# MDR1986VK01 register map
File version: 1.0.2
Registers are 32-bit, read-write, no defined reset value unless marked. A register's access mark holds for its fields unless they carry their own. Offsets are from the block's base; [hi:lo] are bit positions; {n}, {i} and the like mark numbered series; 'fields as' and 'values as' point back to an identical list.

## MDR_PWM0 — MDR_PWM0 description
Base 0x4009E000
Same registers: MDR_PWM{n} {0x4009E000+0x1000*n} (n=1..8)
0x00 TBPRD — TBPRD description
0x08 TBPHS — TBPHS description
0x0C TBCTR — TBCTR description
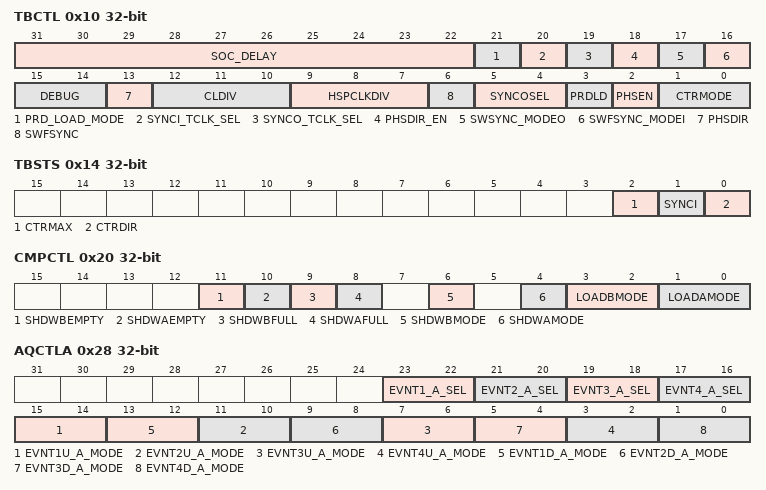
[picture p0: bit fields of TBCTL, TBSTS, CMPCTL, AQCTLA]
0x10 TBCTL — TBCTL description
  [31:22] SOC_DELAY — SOC_DELAY description
  [21] PRD_LOAD_MODE — PRD_LOAD_MODE description
  [20] SYNCI_TCLK_SEL — SYNCI_TCLK_SEL description
  [19] SYNCO_TCLK_SEL — SYNCO_TCLK_SEL description
  [18] PHSDIR_EN — PHSDIR_EN description
  [17] SWSYNC_MODEO — SWSYNC_MODEO description
  [16] SWFSYNC_MODEI — SWFSYNC_MODEI description
  [15:14] DEBUG — DEBUG description
  [13] PHSDIR — PHSDIR description
  [12:10] CLDIV — CLDIV description
  [9:7] HSPCLKDIV — HSPCLKDIV description
  [6] SWFSYNC — SWFSYNC description
  [5:4] SYNCOSEL — SYNCOSEL description
  [3] PRDLD — PRDLD description
  [2] PHSEN — PHSEN description
  [1:0] CTRMODE — CTRMODE description
0x14 TBSTS — TBSTS description
  [2] CTRMAX — CTRMAX description
  [1] SYNCI — SYNCI description
  [0] CTRDIR — CTRDIR description
0x18 CMPA — CMPA description
0x1C CMPB — CMPB description
0x20 CMPCTL — CMPCTL description
  [11] SHDWBEMPTY — SHDWBEMPTY description
  [10] SHDWAEMPTY — SHDWAEMPTY description
  [9] SHDWBFULL — SHDWBFULL description
  [8] SHDWAFULL — SHDWAFULL description
  [6] SHDWBMODE — SHDWBMODE description
  [4] SHDWAMODE — SHDWAMODE description
  [3:2] LOADBMODE — LOADBMODE description
  [1:0] LOADAMODE — LOADAMODE description
0x28 AQCTLA — AQCTLA description
  [25-2n:24-2n] EVNT{n}_A_SEL (n=1..4) — EVNT{n}_A_SEL description
  [19-4n:18-4n] EVNT{n}U_A_MODE (n=1..4) — EVNT{n}U_A_MODE description
  [17-4n:16-4n] EVNT{n}D_A_MODE (n=1..4) — EVNT{n}D_A_MODE description
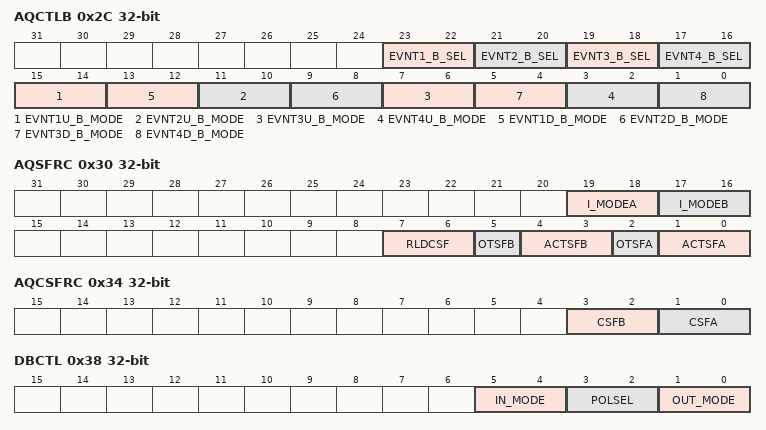
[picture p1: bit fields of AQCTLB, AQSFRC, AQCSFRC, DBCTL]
0x2C AQCTLB — AQCTLB description
  [25-2n:24-2n] EVNT{n}_B_SEL (n=1..4) — EVNT{n}_B_SEL description
  [19-4n:18-4n] EVNT{n}U_B_MODE (n=1..4) — EVNT{n}U_B_MODE description
  [17-4n:16-4n] EVNT{n}D_B_MODE (n=1..4) — EVNT{n}D_B_MODE description
0x30 AQSFRC — AQSFRC description
  [19:18] I_MODEA — I_MODEA description
  [17:16] I_MODEB — I_MODEB description
  [7:6] RLDCSF — RLDCSF description
  [5] OTSFB — OTSFB description
  [4:3] ACTSFB — ACTSFB description
  [2] OTSFA — OTSFA description
  [1:0] ACTSFA — ACTSFA description
0x34 AQCSFRC — AQCSFRC description
  [3:2] CSFB — CSFB description
  [1:0] CSFA — CSFA description
0x38 DBCTL — DBCTL description
  [5:4] IN_MODE — IN_MODE description
  [3:2] POLSEL — POLSEL description
  [1:0] OUT_MODE — OUT_MODE description
0x3C DBRED — DBRED description
0x40 DBFED — DBFED description
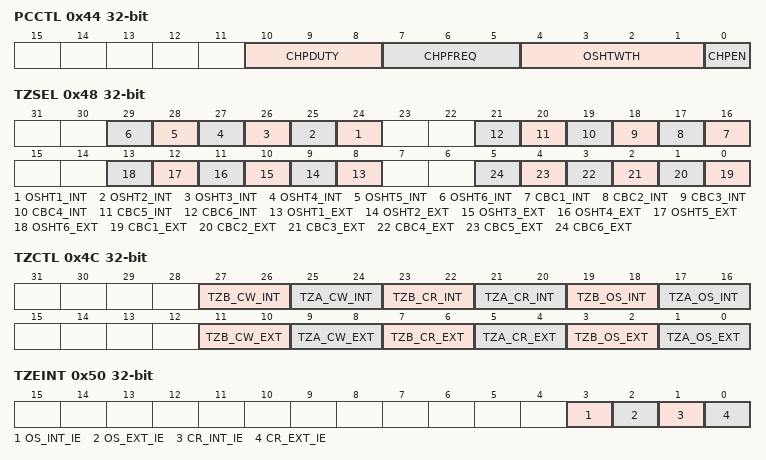
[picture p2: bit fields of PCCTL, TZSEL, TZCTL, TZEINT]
0x44 PCCTL — PCCTL description
  [10:8] CHPDUTY — CHPDUTY description
  [7:5] CHPFREQ — CHPFREQ description
  [4:1] OSHTWTH — OSHTWTH description
  [0] CHPEN — CHPEN description
0x48 TZSEL — TZSEL description
  [n+23] OSHT{n}_INT (n=1..6) — OSHT{n}_INT description
  [n+15] CBC{n}_INT (n=1..6) — CBC{n}_INT description
  [n+7] OSHT{n}_EXT (n=1..6) — OSHT{n}_EXT description
  [n-1] CBC{n}_EXT (n=1..6) — CBC{n}_EXT description
0x4C TZCTL — TZCTL description
  [27:26] TZB_CW_INT — TZB_CW_INT description
  [25:24] TZA_CW_INT — TZA_CW_INT description
  [23:22] TZB_CR_INT — TZB_CR_INT description
  [21:20] TZA_CR_INT — TZA_CR_INT description
  [19:18] TZB_OS_INT — TZB_OS_INT description
  [17:16] TZA_OS_INT — TZA_OS_INT description
  [11:10] TZB_CW_EXT — TZB_CW_EXT description
  [9:8] TZA_CW_EXT — TZA_CW_EXT description
  [7:6] TZB_CR_EXT — TZB_CR_EXT description
  [5:4] TZA_CR_EXT — TZA_CR_EXT description
  [3:2] TZB_OS_EXT — TZB_OS_EXT description
  [1:0] TZA_OS_EXT — TZA_OS_EXT description
0x50 TZEINT — TZEINT description
  [3] OS_INT_IE — OS_INT_IE description
  [2] OS_EXT_IE — OS_EXT_IE description
  [1] CR_INT_IE — CR_INT_IE description
  [0] CR_EXT_IE — CR_EXT_IE description
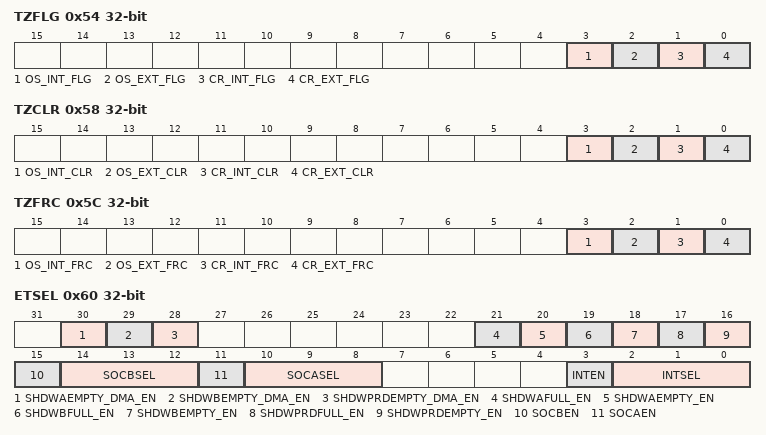
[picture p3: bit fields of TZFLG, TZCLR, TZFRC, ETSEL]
0x54 TZFLG — TZFLG description
  [3] OS_INT_FLG — OS_INT_FLG description
  [2] OS_EXT_FLG — OS_EXT_FLG description
  [1] CR_INT_FLG — CR_INT_FLG description
  [0] CR_EXT_FLG — CR_EXT_FLG description
0x58 TZCLR — TZCLR description
  [3] OS_INT_CLR — OS_INT_CLR description
  [2] OS_EXT_CLR — OS_EXT_CLR description
  [1] CR_INT_CLR — CR_INT_CLR description
  [0] CR_EXT_CLR — CR_EXT_CLR description
0x5C TZFRC — TZFRC description
  [3] OS_INT_FRC — OS_INT_FRC description
  [2] OS_EXT_FRC — OS_EXT_FRC description
  [1] CR_INT_FRC — CR_INT_FRC description
  [0] CR_EXT_FRC — CR_EXT_FRC description
0x60 ETSEL — ETSEL description
  [30] SHDWAEMPTY_DMA_EN — SHDWAEMPTY_DMA_EN description
  [29] SHDWBEMPTY_DMA_EN — SHDWBEMPTY_DMA_EN description
  [28] SHDWPRDEMPTY_DMA_EN — SHDWPRDEMPTY_DMA_EN description
  [21] SHDWAFULL_EN — SHDWAFULL_EN description
  [20] SHDWAEMPTY_EN — SHDWAEMPTY_EN description
  [19] SHDWBFULL_EN — SHDWBFULL_EN description
  [18] SHDWBEMPTY_EN — SHDWBEMPTY_EN description
  [17] SHDWPRDFULL_EN — SHDWPRDFULL_EN description
  [16] SHDWPRDEMPTY_EN — SHDWPRDEMPTY_EN description
  [15] SOCBEN — SOCBEN description
  [14:12] SOCBSEL — SOCBSEL description
  [11] SOCAEN — SOCAEN description
  [10:8] SOCASEL — SOCASEL description
  [3] INTEN — INTEN description
  [2:0] INTSEL — INTSEL description
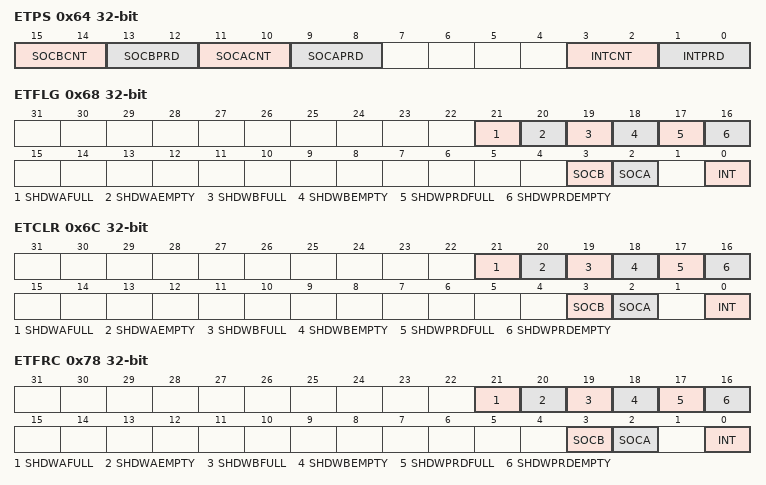
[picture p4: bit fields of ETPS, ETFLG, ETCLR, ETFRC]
0x64 ETPS — ETPS description
  [15:14] SOCBCNT — SOCBCNT description
  [13:12] SOCBPRD — SOCBPRD description
  [11:10] SOCACNT — SOCACNT description
  [9:8] SOCAPRD — SOCAPRD description
  [3:2] INTCNT — INTCNT description
  [1:0] INTPRD — INTPRD description
0x68 ETFLG — ETFLG description
  [21] SHDWAFULL — SHDWAFULL description
  [20] SHDWAEMPTY — SHDWAEMPTY description
  [19] SHDWBFULL — SHDWBFULL description
  [18] SHDWBEMPTY — SHDWBEMPTY description
  [17] SHDWPRDFULL — SHDWPRDFULL description
  [16] SHDWPRDEMPTY — SHDWPRDEMPTY description
  [3] SOCB — SOCB description
  [2] SOCA — SOCA description
  [0] INT — INT description
0x6C ETCLR — ETCLR description
  fields as ETFLG
0x78 ETFRC — ETFRC description
  fields as ETFLG
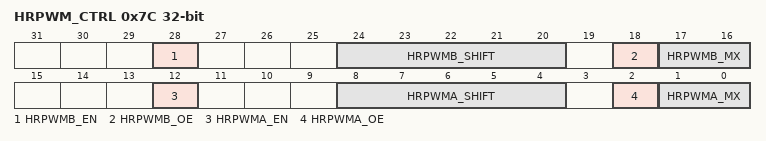
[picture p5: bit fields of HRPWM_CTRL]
0x7C HRPWM_CTRL — HRPWM_CTRL description
  [28] HRPWMB_EN — HRPWMB_EN description
  [24:20] HRPWMB_SHIFT — HRPWMB_SHIFT description
  [18] HRPWMB_OE — HRPWMB_OE description
  [17:16] HRPWMB_MX — HRPWMB_MX description
  [12] HRPWMA_EN — HRPWMA_EN description
  [8:4] HRPWMA_SHIFT — HRPWMA_SHIFT description
  [2] HRPWMA_OE — HRPWMA_OE description
  [1:0] HRPWMA_MX — HRPWMA_MX description
